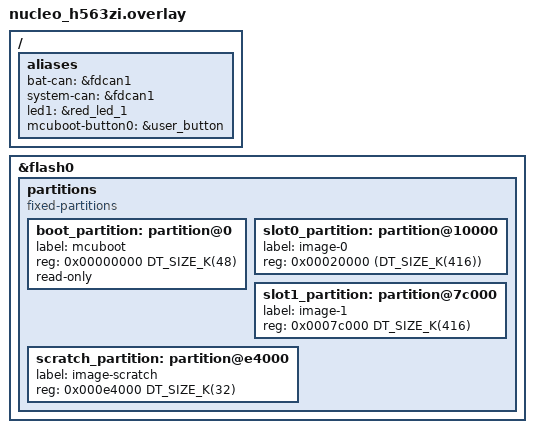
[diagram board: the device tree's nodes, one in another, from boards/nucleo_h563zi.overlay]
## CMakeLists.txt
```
#-------------------------------------------------------------------------------
# Zephyr Example Application
#
# Copyright (c) 2021 Nordic Semiconductor ASA
# SPDX-License-Identifier: Apache-2.0

cmake_minimum_required(VERSION 3.13.1)
find_package(Zephyr REQUIRED HINTS $ENV{ZEPHYR_BASE})

project(app LANGUAGES C)

target_sources(app PRIVATE src/main.c)
target_sources(app PRIVATE src/can.c)
target_sources(app PRIVATE src/sha256.c)
target_sources(app PRIVATE src/utils.c)
```

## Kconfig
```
# Copyright (c) 2021 Nordic Semiconductor ASA
# SPDX-License-Identifier: Apache-2.0
#
# This file is the application Kconfig entry point. All application Kconfig
# options can be defined here or included via other application Kconfig files.
# You can browse these options using the west targets menuconfig (terminal) or
# guiconfig (GUI).

menu "Zephyr"
source "Kconfig.zephyr"

config SAMPLE_CAN_TX_QUEUE_SIZE
	int "Maximum number of CAN frames to enqueue"
	default 3
	range 1 3
	help
	  Maximum number of CAN frames to enqueue for transmission.


endmenu

module = APP
module-str = APP
source "subsys/logging/Kconfig.template.log_config"
```

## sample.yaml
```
# This file is provided so that the application can be compiled using Twister,
# the Zephyr testing tool. In this file, multiple combinations can be specified,
# so that you can easily test all of them locally or in CI.
sample:
  description: CAN bootloader sample application
  name: zcan-boot
common:
  build_only: true
  integration_platforms:
    - stm32h563zi
tests:
  app.default: {}
  app.debug:
    extra_overlay_confs:
      - debug.conf
```

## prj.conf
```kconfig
CONFIG_LOG=y
CONFIG_ASSERT=n
CONFIG_DEBUG=n
CONFIG_DEBUG_THREAD_INFO=n
CONFIG_MAIN_STACK_SIZE=2560
CONFIG_CAN=y
CONFIG_SERIAL=y

CONFIG_FLASH=y
CONFIG_FLASH_MAP=y
CONFIG_FLASH_PAGE_LAYOUT=y
```

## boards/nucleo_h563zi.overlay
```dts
/ {
    aliases {
		bat-can = &fdcan1;
		system-can = &fdcan1;
		led1 = &red_led_1;
		mcuboot-button0 = &user_button;
    };
};

&flash0 {
	partitions {
		compatible = "fixed-partitions";
		#address-cells = <1>;
		#size-cells = <1>;

		boot_partition: partition@0 {
			label = "mcuboot";
			reg = <0x00000000 DT_SIZE_K(48)>;
			read-only;
		};
		/* The MCUBoot swap-move algorithm uses the last 2 sectors
		 * of the primary slot0 for swap status and move.
		 */
		slot0_partition: partition@10000 {
			label = "image-0";
			reg = <0x00020000 (DT_SIZE_K(416))>;
		};
		slot1_partition: partition@7c000 {
			label = "image-1";
			reg = <0x0007c000 DT_SIZE_K(416)>;
		};
		scratch_partition: partition@e4000 {
			label = "image-scratch";
			reg = <0x000e4000 DT_SIZE_K(32)>;
		};
	};
};
```

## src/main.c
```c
/**
 * @file main.c
 * @author Sarthak Et (et-sarthak)
 * @brief Custom bootloader implementation for firmware updates over CAN bus
 * @version 1.0
 * @date 2024-10-05
 * 
 */

#include <string.h>
#include <zephyr/drivers/flash.h>
#include <zephyr/kernel.h>
#include <zephyr/logging/log.h>

#include "../../include/can.h"
#include "../../include/flash_config.h"
#include "../../include/sha256.h"
#include "../../include/utils.h"

LOG_MODULE_REGISTER(main, CONFIG_LOG_MAX_LEVEL);

/*-------------------------MACROS-----------------------------------*/

#define FL_HEADER_LENGTH     0x400U
#define FL_APP_SLOT_ONE_ADDR 0x20000U
#define FL_APP_SLOT_TWO_ADDR 0x7c000U
#define FL_APP_SLOT_SIZE     0x20000U
#define FL_STORAGE_AREA      0x3c000U
#define FL_UNIT_ADDR         16U
#define FL_SECTOR_SIZE       8192U
#define FL_BASE_ADDRESS      0x08000000U
#define FLASH_DEVICE_NODE    DT_CHOSEN(zephyr_flash_controller)

const struct device* flash_dev = DEVICE_DT_GET(FLASH_DEVICE_NODE);
struct tc_sha256_state_struct sha_ctx;
struct tc_sha256_state_struct new_firm;

typedef struct fl_data {
    uint8_t hashA[2][32];
    uint8_t versionA[2][3];
    int size_in_sectors[2];
    bool is_update_req;
}fl_data_t;

typedef enum DfuState {
    DfuStateWaitForHashData = 0,
    DfuStateWaitForFlashData,
    DfuStateWaitForFlashUpdateCmd,
    DfuStateWaitForCheckHashCmd,
    DfuStatesJumpToApp,
    DfuStateWaiting,
} DfuState_e;

fl_data_t fl_data = {
    .hashA = {{0}},
    .versionA = {{0}},
    .size_in_sectors = {0},
};
int cnt = 0;
int slot_index;
int size_in_sectors;
uint8_t hash_value[32] = {0};
uint8_t output_hash[32] = {0};
uint32_t sector_data[FL_SECTOR_SIZE / 4] = {0};
uint32_t app_slot_addr[2] = {FL_APP_SLOT_ONE_ADDR, FL_APP_SLOT_TWO_ADDR};

/*-------------------------------LOCAL API----------------------------------*/

/**
 * @brief           Read data from flash memory
 * @param addr      flash address to read from
 * @param data      pointer to data buffer to store read data
 * @param size      size of data to read in bytes
 * @return          report error in case of failure
 */

 FuncStatus flash_read_data(uint32_t addr, uint32_t* data, uint32_t size) {
    if (addr % FL_UNIT_ADDR != 0) {
        LOG_ERR("Address or size not aligned to FLASH_UNIT_ADDR (%d)\n", FL_UNIT_ADDR);
        return FuncStatusInvalidArgument;
    }
    for (uint32_t i = 0; i < size; i += FL_UNIT_ADDR) {
        int rc = flash_read(flash_dev, addr + i, (uint8_t*)data + i, FL_UNIT_ADDR);
        if (rc != 0) {
            LOG_ERR("Flash read failed (rc=%d)\n", rc);
            return FuncStatusError;
        }
    }
    return FuncStatusOk;
}

/**
 * @brief           Write data to flash memory (sector erase before write)
 * @param addr      flash address to read from
 * @param data      pointer to data buffer to store read data
 * @param size      size of data to read in bytes
 * @return          report error in case of failure
 */
FuncStatus flash_write_sector(uint32_t addr, const uint32_t* data, uint32_t size) {
    if (addr % FL_UNIT_ADDR != 0) {
        LOG_ERR("Address or size not aligned to FLASH_UNIT_ADDR (%d)\n", FL_UNIT_ADDR);
        return FuncStatusInvalidArgument;
    }
    int rc = flash_erase(flash_dev, addr, FL_SECTOR_SIZE);
    if (rc != 0) {
        LOG_ERR("Flash erase failed (rc=%d)\n", rc);
        return FuncStatusError;
    }
    for (uint32_t i = 0; i < size; i += FL_UNIT_ADDR) {
        int rc = flash_write(flash_dev, addr + i, (const uint8_t*)data + i, FL_UNIT_ADDR);
        if (rc != 0) {
            LOG_ERR("Flash write failed at offset %u (rc=%d)\n", i, rc);
            return FuncStatusError;
        }
    }
    return FuncStatusOk;
}


/**
 * @brief            Store incoming hash data
 * @param data       Pointer to incoming data
 * @return           FuncStatus indicating the status of the operation
 */

FuncStatus store_hash(uint8_t* data) {
    if (cnt == 32) {
        slot_index = data[0];
        fl_data.size_in_sectors[slot_index] = data[1];
        memcpy(&fl_data.versionA[slot_index], &data[2], sizeof(fl_data.versionA[0]));
        memcpy(&fl_data.hashA[slot_index][0], &hash_value, sizeof(fl_data.hashA[0]));
        LOG_INF("version %x %x %x", fl_data.versionA[slot_index][0],
                fl_data.versionA[slot_index][1], fl_data.versionA[slot_index][2]);
        LOG_INF("current slot %d", slot_index);
        cnt = 0;
        return FuncStatusCompleted;
    } else {
        memcpy(&hash_value[cnt], data, sizeof(uint64_t));
        cnt = cnt + 8;
        return FuncStatusInProcess;
    }
}
/**
 * @brief             Store incoming flash data into a local buffer
 * @param data        Pointer to incoming data
 * @return            FuncStatus indicating the status of the operation
 */
FuncStatus store_flash(uint8_t* data) {
    if (cnt < (FL_SECTOR_SIZE / 4)) {
        memcpy(&sector_data[cnt], data, sizeof(uint64_t));
        cnt = cnt + 2;
        if (cnt == (FL_SECTOR_SIZE / 4)) {
            return FuncStatusCompleted;
        }
        return FuncStatusInProcess;
    } else if (cnt >= (FL_SECTOR_SIZE / 4)) {
        LOG_ERR("local buffer is full");
        return FuncStatusOutOfMemory;
    }
    return FuncStatusError;
}

/**
 * @brief               Update flash memory with data from the local buffer
 * @param slot_index    Index of the application slot to update
 * @return              FuncStatus indicating the status of the operation
 */

FuncStatus update_flash(uint8_t slot_index) {
    cnt = 0;
    static uint32_t sector_number = 0;

    LOG_INF("writing to flash_sector %d", sector_number);
    tc_sha256_update(&new_firm, (uint8_t*)sector_data, sizeof(sector_data));
    if (flash_write_sector(app_slot_addr[slot_index] + (FL_SECTOR_SIZE * sector_number),
                           sector_data, FL_SECTOR_SIZE) == FuncStatusOk) {
        sector_number++;
        memset(sector_data, 0xFFFFFFFF, sizeof(sector_data));
        if (fl_data.size_in_sectors[slot_index] == sector_number) {
            // All sectors written
            return FuncStatusCompleted;
        }
        return FuncStatusInProcess;
    }
    return FuncStatusError;
}

/**
 * @brief               Check if the computed hash matches the expected hash
 * @return              FuncStatus indicating whether the hashes match
 */
FuncStatus check_hash() {
    tc_sha256_final(output_hash, &new_firm);
    for (int i = 0; i < sizeof(output_hash); i++) {
        k_msleep(10);
        LOG_INF("%02x\t%02x ", output_hash[i], hash_value[i]);
    }
    if (memcmp(output_hash, hash_value, sizeof(output_hash)) == 0) return FuncStatusOk;
    return FuncStatusError;
}

/**
 * @brief               Jump to the application code in the specified slot
 * @param slot_index    Index of the application slot to jump to
 */
void jump_to_app(uint8_t slot_index) {
    LOG_INF("app_slot %x", app_slot_addr[slot_index]);
    void (*app_reset_handler)();
    uint32_t msp =
        *(volatile uint32_t*)(FL_BASE_ADDRESS + app_slot_addr[slot_index] + FL_HEADER_LENGTH);
    uint32_t reset_handler =
        *(volatile uint32_t*)(FL_BASE_ADDRESS + app_slot_addr[slot_index] + FL_HEADER_LENGTH + 4) |
        0x1;

    LOG_INF("msp: %x\n", msp);
    LOG_INF("reset_handler: %x\n", reset_handler);

    // Set the Vector Table Offset Register to the application's vector table
    SCB->VTOR = FL_BASE_ADDRESS + app_slot_addr[slot_index] + FL_HEADER_LENGTH;

    app_reset_handler = (void (*)())reset_handler;
    __disable_irq();
    HAL_DeInit();
    __set_MSP(msp);
    __DSB();
    __ISB();

    app_reset_handler();
}

/**
 * @brief               Find the latest valid firmware version
 * @param version       Pointer to the fl_data structure containing version information
 * @return              Index of the latest valid version (0 or 1), or -1 if both are invalid
 */
static inline int find_latest_version(struct fl_data* version) {
    int versionA_val =
        (version->versionA[0][0] << 16) | (version->versionA[0][1] << 8) | version->versionA[0][2];
    int versionB_val =
        (version->versionA[1][0] << 16) | (version->versionA[1][1] << 8) | version->versionA[1][2];
    int isA_valid = (versionA_val != 0xFFFFFF);
    int isB_valid = (versionB_val != 0xFFFFFF);

    if (isA_valid && !isB_valid) return 0;      // Only A is valid
    if (!isA_valid && isB_valid) return 1;      // Only B is valid
    if (!isA_valid && !isB_valid) return (-1);  // Both invalid: default to A`
    return (memcmp(&versionA_val, &versionB_val, sizeof(int)) > 0) ? 0 : 1;
}

/*-----------------------------DFU STATE_MACHINE--------------------------------*/

/**
 * @brief               Poll for incoming data and manage the DFU state machine
 * @return              FuncStatus indicating the status of the operation
 */
FuncStatus poll_data() {
    FuncStatus fs = FuncStatusNotReady;
    static DfuState_e state = DfuStateWaitForHashData;
    struct frame_packed packed_frame = {0};
    fs = k_msgq_get(&can_receive_q, &packed_frame, K_FOREVER);
    if (fs != FuncStatusOk) {
        LOG_ERR("k_msgq_get failed with error: %d", fs);
        return fs;
    }

    switch (state) {
    case DfuStateWaiting:
        state = packed_frame.state;
        break;

    case DfuStateWaitForHashData:
        if (packed_frame.state != PacketTypeHashData) {
            LOG_WRN("%s: %d: Invalid packet type: %d", __FUNCTION__, __LINE__, packed_frame.state);
            return FuncStatusInvalidState;
        }
        fs = store_hash(packed_frame.data);
        if (fs == FuncStatusCompleted) {
            state = DfuStateWaitForFlashData;
        }
        break;

    case DfuStateWaitForFlashData:
        if (packed_frame.state != PacketTypeFlashData) {
            LOG_WRN("%s: %d: Invalid packet type: %d", __FUNCTION__, __LINE__, packed_frame.state);
            return FuncStatusInvalidState;
        }
        fs = store_flash(packed_frame.data);
        if (fs == FuncStatusCompleted) {
            state = DfuStateWaitForFlashUpdateCmd;
        } else if (fs == FuncStatusInProcess) {
            return fs;
        } else {
            LOG_ERR("Error storing flash data: %d", fs);
            return fs;
        }
        break;

    case DfuStateWaitForFlashUpdateCmd:
        fs = update_flash(slot_index);
        if (fs == FuncStatusCompleted) {
            LOG_INF("All Flash sectors update successful for slot %d", slot_index);
            state = DfuStateWaitForCheckHashCmd;
        } else if (fs == FuncStatusInProcess) {
            state = DfuStateWaitForFlashData;
        } else {
            LOG_ERR("Error updating flash: %d", fs);
            return fs;
        }
        break;

    case DfuStateWaitForCheckHashCmd:
        if (packed_frame.state != PacketTypeCheckHashCmd) {
            LOG_WRN("%s: %d: Invalid packet type: %d", __FUNCTION__, __LINE__, packed_frame.state);
            return FuncStatusInvalidState;
        }
        fs = check_hash();
        if (fs == FuncStatusOk) {
            fl_data.is_update_req = false;
            fs = flash_write_sector(FL_STORAGE_AREA, (uint32_t*)&fl_data, sizeof(fl_data));
            k_msleep(1000);
            if (fs == FuncStatusOk)
                jump_to_app(slot_index);
            else
                LOG_ERR("%s: %d: Failed to write flash data to storage area: %d", __FUNCTION__,
                        __LINE__, fs);
        } else {
            LOG_ERR("Hash check failed.");
        }
        break;

    default:
        LOG_WRN("Unknown CAN ID: %x", packed_frame.state);
        return FuncStatusError;  // Unknown CAN ID
    }
    return FuncStatusOk;
}

/*-----------------------------MAIN THREAD--------------------------------*/

/**
 * @brief Main function to initialize the bootloader and manage firmware updates
 */
int main() {
    int version_idx = 0;
    static uint32_t fl_read_arr[FL_SECTOR_SIZE / 4] = {0};
    if (!tc_sha256_init(&sha_ctx)) {
        LOG_ERR("hash init failed");
    }
    if (!device_is_ready(flash_dev)) {
        printk("Flash device not ready!\n");
        return -ENODEV;
    }
    if (!tc_sha256_init(&new_firm)) {
        LOG_ERR("hash init failed");
    }
    can_init();
    LOG_INF("Welcome to the custom bootloader!");
    k_msleep(10);
    flash_read_data(FL_STORAGE_AREA, (uint32_t*)&fl_data, sizeof(fl_data));

    version_idx = find_latest_version(&fl_data);
    LOG_INF("version_idx: %d", version_idx);
    LOG_INF("update req value %d:", fl_data.is_update_req);
    if (version_idx == (-1) || fl_data.is_update_req == true) {
        LOG_INF("DFU ENTRY");
        k_msleep(10);
        goto polling_start;
    }
    size_in_sectors = fl_data.size_in_sectors[version_idx];
    for (uint8_t i = 0; i < size_in_sectors; i++) {
        flash_read_data((app_slot_addr[version_idx]) + (i * FL_SECTOR_SIZE), fl_read_arr,
                        FL_SECTOR_SIZE);
        tc_sha256_update(&sha_ctx, fl_read_arr, sizeof(fl_read_arr));
    }
    tc_sha256_final(output_hash, &sha_ctx);

    int check = (version_idx == 0) ? memcmp(fl_data.hashA[0], output_hash, sizeof(output_hash))
                                   : memcmp(fl_data.hashA[1], output_hash, sizeof(output_hash));

    if (check == 0) {
        LOG_INF("Hash matches, jumping to app slot %d", version_idx);
        flash_write_sector(FL_STORAGE_AREA, (uint32_t*)&fl_data, sizeof(fl_data));
        k_msleep(1000);
        jump_to_app(version_idx);
    } else {
        LOG_WRN("Hash mismatch, continuing bootloader operations");
    }

polling_start:
    LOG_INF("Starting polling loop...");
    FuncStatus fs = FuncStatusOk;
    while (1) {
        if (fs >= FuncStatusOk) poll_data();
        k_msleep(5);
    }
    LOG_WRN("Unexpected Exit$$$");
    return 0;
}
```

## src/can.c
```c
/**
 * @file can.c
 * @author Sarthak Et (et-sarthak)
 * @brief CAN interface implementation for system communication
 * @version 1.0
 * @date 2024-10-05
 * 
 */

#include "../../include/can.h"
#include "../../include/flash_config.h"

#include <zephyr/device.h>
#include <zephyr/drivers/can.h>
#include <zephyr/kernel.h>
#include <zephyr/logging/log.h>
#include <zephyr/sys/byteorder.h>
#include <zephyr/sys/printk.h>

#define SYSTEM_CANBUS_NODE  DT_ALIAS(system_can)
#define BATTERY_CANBUS_NODE DT_ALIAS(bat_can)
#define CAN_BITRATE_500    500000

K_MSGQ_DEFINE(can_receive_q, sizeof(struct frame_packed), 20, 4);

LOG_MODULE_REGISTER(can, CONFIG_LOG_MAX_LEVEL);

int err;
int sys_filter_id;
int batt_filter_id;

const struct device* system_can_dev = DEVICE_DT_GET(SYSTEM_CANBUS_NODE);
const struct device* batt_can_dev = DEVICE_DT_GET(BATTERY_CANBUS_NODE);

const struct can_filter rx_filter = {.flags = 0U, .id = 0x220, .mask = 0x000};

/**
 * @brief            Callback function to handle received CAN frames for system messages
 * @param dev        Pointer to the CAN device
 * @param frame      Pointer to the received CAN frame
 * @param user_data  User data pointer (not used)
 */
void can_sys_callback(const struct device* dev, struct can_frame* frame, void* user_data) {
    struct frame_packed packed_frame = {0};
    packed_frame.state = ((frame->id - 0x100) / 4);
    memcpy(&packed_frame.data, frame->data, sizeof(frame->data));
    k_msgq_put(&can_receive_q, &packed_frame, K_NO_WAIT);
}

void can_batt_callback(const struct device* dev, struct can_frame* frame, void* user_data) {
    LOG_INF("Received battery CAN frame with ID: 0x%03X", frame->id);
}

/**
 * @brief            Initialize the CAN interfaces for system and battery communication
 * @return           FuncStatus indicating the status of the initialization
 */
FuncStatus can_init() {
    sys_filter_id = can_add_rx_filter(system_can_dev, can_sys_callback, NULL, &rx_filter);
    batt_filter_id = can_add_rx_filter(batt_can_dev, can_batt_callback, NULL, &rx_filter);
    if (!device_is_ready(system_can_dev)) {
        LOG_WRN("CAN device not ready");
    }
    if (!device_is_ready(batt_can_dev)) {
        LOG_WRN("CAN device not ready");
    }
    err = can_set_bitrate(system_can_dev, CAN_BITRATE_500);
    if (err != 0) {
        LOG_WRN("%s %d Error in setting system CAN bitrate %d", __FUNCTION__, __LINE__, err);
    }
    err = can_set_bitrate(batt_can_dev, CAN_BITRATE_500);
    if (err != 0) {
        LOG_WRN("%s %d Error in setting system CAN bitrate %d", __FUNCTION__, __LINE__, err);
    }
    err = can_start(batt_can_dev);
    if (err != 0) {
        LOG_WRN("Error starting CAN controller (err %d)", err);
    }
    err = can_start(system_can_dev);
    if (err != 0) {
        LOG_WRN("Error starting CAN controller (err %d)", err);
        return FuncStatusError;
    }
    return FuncStatusOk;
}


// Not in use currently
/*
int can_write(uint32_t id, uint8_t* data) {
    struct can_frame frame = {0};
    frame.id = id;
    frame.dlc = 8;  // Data length code, max 8 bytes
    memcpy(frame.data, data, frame.dlc);
    return can_send(system_can_dev, &frame, K_FOREVER, NULL, NULL);
}

int send_ack() {
    struct can_frame frame = {0};
    frame.id = 0x020;          // Acknowledgment frame ID
    frame.dlc = 8;             // Data length code, max 8 bytes
    uint32_t ack_data = 0x01;  // Example data
    uint32_t crc = crc32_uint32(ack_data);
    memcpy(frame.data, &ack_data, sizeof(ack_data));
    memcpy(frame.data + sizeof(ack_data), &crc, sizeof(crc));
    return can_send(system_can_dev, &frame, K_FOREVER, NULL, NULL);
}

int send_nack() {
    struct can_frame frame = {0};
    frame.id = 0x020;           // acknowledgment frame ID
    frame.dlc = 8;              // Data length code, max 8 bytes
    uint32_t nack_data = 0x00;  // Example data
    uint32_t crc = crc32_uint32(nack_data);
    memcpy(frame.data, &nack_data, sizeof(nack_data));
    memcpy(frame.data + sizeof(nack_data), &crc, sizeof(crc));

    return can_send(system_can_dev, &frame, K_FOREVER, NULL, NULL);
}
*/
```

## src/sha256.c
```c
/* sha256.c - TinyCrypt SHA-256 crypto hash algorithm implementation */

/*
 *  Copyright (C) 2017 by Intel Corporation, All Rights Reserved.
 *
 *  Redistribution and use in source and binary forms, with or without
 *  modification, are permitted provided that the following conditions are met:
 *
 *    - Redistributions of source code must retain the above copyright notice,
 *     this list of conditions and the following disclaimer.
 *
 *    - Redistributions in binary form must reproduce the above copyright
 *    notice, this list of conditions and the following disclaimer in the
 *    documentation and/or other materials provided with the distribution.
 *
 *    - Neither the name of Intel Corporation nor the names of its contributors
 *    may be used to endorse or promote products derived from this software
 *    without specific prior written permission.
 *
 *  THIS SOFTWARE IS PROVIDED BY THE COPYRIGHT HOLDERS AND CONTRIBUTORS "AS IS"
 *  AND ANY EXPRESS OR IMPLIED WARRANTIES, INCLUDING, BUT NOT LIMITED TO, THE
 *  IMPLIED WARRANTIES OF MERCHANTABILITY AND FITNESS FOR A PARTICULAR PURPOSE
 *  ARE DISCLAIMED. IN NO EVENT SHALL THE COPYRIGHT OWNER OR CONTRIBUTORS BE
 *  LIABLE FOR ANY DIRECT, INDIRECT, INCIDENTAL, SPECIAL, EXEMPLARY, OR
 *  CONSEQUENTIAL DAMAGES (INCLUDING, BUT NOT LIMITED TO, PROCUREMENT OF
 *  SUBSTITUTE GOODS OR SERVICES; LOSS OF USE, DATA, OR PROFITS; OR BUSINESS
 *  INTERRUPTION) HOWEVER CAUSED AND ON ANY THEORY OF LIABILITY, WHETHER IN
 *  CONTRACT, STRICT LIABILITY, OR TORT (INCLUDING NEGLIGENCE OR OTHERWISE)
 *  ARISING IN ANY WAY OUT OF THE USE OF THIS SOFTWARE, EVEN IF ADVISED OF THE
 *  POSSIBILITY OF SUCH DAMAGE.
 */


 #include "../../include/sha256.h"
 #include "../../include/utils.h"
#include "constants.h"
// #include <zephyr/kernel.h>

static void compress(unsigned int *iv, const uint8_t *data);

int tc_sha256_init(TCSha256State_t s)
{
	/* input sanity check: */
	if (s == (TCSha256State_t) 0) {
		return TC_CRYPTO_FAIL;
	}

	/*
	 * Setting the initial state values.
	 * These values correspond to the first 32 bits of the fractional parts
	 * of the square roots of the first 8 primes: 2, 3, 5, 7, 11, 13, 17
	 * and 19.
	 */
	_set((uint8_t *) s, 0x00, sizeof(*s));
	s->iv[0] = 0x6a09e667;
	s->iv[1] = 0xbb67ae85;
	s->iv[2] = 0x3c6ef372;
	s->iv[3] = 0xa54ff53a;
	s->iv[4] = 0x510e527f;
	s->iv[5] = 0x9b05688c;
	s->iv[6] = 0x1f83d9ab;
	s->iv[7] = 0x5be0cd19;

	return TC_CRYPTO_SUCCESS;
}

int tc_sha256_update(TCSha256State_t s, const uint8_t *data, size_t datalen)
{
	/* input sanity check: */
	if (s == (TCSha256State_t) 0 ||
	    data == (void *) 0) {
		return TC_CRYPTO_FAIL;
	} else if (datalen == 0) {
		return TC_CRYPTO_SUCCESS;
	}

	while (datalen-- > 0) {
		s->leftover[s->leftover_offset++] = *(data++);
		// printf("data = %02x\n", s->leftover[s->leftover_offset - 1]);
		// k_msleep(2);
		if (s->leftover_offset >= TC_SHA256_BLOCK_SIZE) {
			compress(s->iv, s->leftover);
			s->leftover_offset = 0;
			s->bits_hashed += (TC_SHA256_BLOCK_SIZE << 3);
		}
	}

	return TC_CRYPTO_SUCCESS;
}

int tc_sha256_final(uint8_t *digest, TCSha256State_t s)
{
	unsigned int i;

	/* input sanity check: */
	if (digest == (uint8_t *) 0 ||
	    s == (TCSha256State_t) 0) {
		return TC_CRYPTO_FAIL;
	}

	s->bits_hashed += (s->leftover_offset << 3);

	s->leftover[s->leftover_offset++] = 0x80; /* always room for one byte */
	if (s->leftover_offset > (sizeof(s->leftover) - 8)) {
		/* there is not room for all the padding in this block */
		_set(s->leftover + s->leftover_offset, 0x00,
		     sizeof(s->leftover) - s->leftover_offset);
		compress(s->iv, s->leftover);
		s->leftover_offset = 0;
	}

	/* add the padding and the length in big-Endian format */
	_set(s->leftover + s->leftover_offset, 0x00,
	     sizeof(s->leftover) - 8 - s->leftover_offset);
	s->leftover[sizeof(s->leftover) - 1] = (uint8_t)(s->bits_hashed);
	s->leftover[sizeof(s->leftover) - 2] = (uint8_t)(s->bits_hashed >> 8);
	s->leftover[sizeof(s->leftover) - 3] = (uint8_t)(s->bits_hashed >> 16);
	s->leftover[sizeof(s->leftover) - 4] = (uint8_t)(s->bits_hashed >> 24);
	s->leftover[sizeof(s->leftover) - 5] = (uint8_t)(s->bits_hashed >> 32);
	s->leftover[sizeof(s->leftover) - 6] = (uint8_t)(s->bits_hashed >> 40);
	s->leftover[sizeof(s->leftover) - 7] = (uint8_t)(s->bits_hashed >> 48);
	s->leftover[sizeof(s->leftover) - 8] = (uint8_t)(s->bits_hashed >> 56);

	/* hash the padding and length */
	compress(s->iv, s->leftover);

	/* copy the iv out to digest */
	for (i = 0; i < TC_SHA256_STATE_BLOCKS; ++i) {
		unsigned int t = *((unsigned int *) &s->iv[i]);
		*digest++ = (uint8_t)(t >> 24);
		*digest++ = (uint8_t)(t >> 16);
		*digest++ = (uint8_t)(t >> 8);
		*digest++ = (uint8_t)(t);
	}

	/* destroy the current state */
	_set(s, 0, sizeof(*s));

	return TC_CRYPTO_SUCCESS;
}

/*
 * Initializing SHA-256 Hash constant words K.
 * These values correspond to the first 32 bits of the fractional parts of the
 * cube roots of the first 64 primes between 2 and 311.
 */
static const unsigned int k256[64] = {
	0x428a2f98, 0x71374491, 0xb5c0fbcf, 0xe9b5dba5, 0x3956c25b, 0x59f111f1,
	0x923f82a4, 0xab1c5ed5, 0xd807aa98, 0x12835b01, 0x243185be, 0x550c7dc3,
	0x72be5d74, 0x80deb1fe, 0x9bdc06a7, 0xc19bf174, 0xe49b69c1, 0xefbe4786,
	0x0fc19dc6, 0x240ca1cc, 0x2de92c6f, 0x4a7484aa, 0x5cb0a9dc, 0x76f988da,
	0x983e5152, 0xa831c66d, 0xb00327c8, 0xbf597fc7, 0xc6e00bf3, 0xd5a79147,
	0x06ca6351, 0x14292967, 0x27b70a85, 0x2e1b2138, 0x4d2c6dfc, 0x53380d13,
	0x650a7354, 0x766a0abb, 0x81c2c92e, 0x92722c85, 0xa2bfe8a1, 0xa81a664b,
	0xc24b8b70, 0xc76c51a3, 0xd192e819, 0xd6990624, 0xf40e3585, 0x106aa070,
	0x19a4c116, 0x1e376c08, 0x2748774c, 0x34b0bcb5, 0x391c0cb3, 0x4ed8aa4a,
	0x5b9cca4f, 0x682e6ff3, 0x748f82ee, 0x78a5636f, 0x84c87814, 0x8cc70208,
	0x90befffa, 0xa4506ceb, 0xbef9a3f7, 0xc67178f2
};

static inline unsigned int ROTR(unsigned int a, unsigned int n)
{
	return (((a) >> n) | ((a) << (32 - n)));
}

#define Sigma0(a)(ROTR((a), 2) ^ ROTR((a), 13) ^ ROTR((a), 22))
#define Sigma1(a)(ROTR((a), 6) ^ ROTR((a), 11) ^ ROTR((a), 25))
#define sigma0(a)(ROTR((a), 7) ^ ROTR((a), 18) ^ ((a) >> 3))
#define sigma1(a)(ROTR((a), 17) ^ ROTR((a), 19) ^ ((a) >> 10))

#define Ch(a, b, c)(((a) & (b)) ^ ((~(a)) & (c)))
#define Maj(a, b, c)(((a) & (b)) ^ ((a) & (c)) ^ ((b) & (c)))

static inline unsigned int BigEndian(const uint8_t **c)
{
	unsigned int n = 0;

	n = (((unsigned int)(*((*c)++))) << 24);
	n |= ((unsigned int)(*((*c)++)) << 16);
	n |= ((unsigned int)(*((*c)++)) << 8);
	n |= ((unsigned int)(*((*c)++)));
	return n;
}

static void compress(unsigned int *iv, const uint8_t *data)
{
	unsigned int a, b, c, d, e, f, g, h;
	unsigned int s0, s1;
	unsigned int t1, t2;
	unsigned int work_space[16];
	unsigned int n;
	unsigned int i;

	a = iv[0]; b = iv[1]; c = iv[2]; d = iv[3];
	e = iv[4]; f = iv[5]; g = iv[6]; h = iv[7];

	for (i = 0; i < 16; ++i) {
		n = BigEndian(&data);
		t1 = work_space[i] = n;
		t1 += h + Sigma1(e) + Ch(e, f, g) + k256[i];
		t2 = Sigma0(a) + Maj(a, b, c);
		h = g; g = f; f = e; e = d + t1;
		d = c; c = b; b = a; a = t1 + t2;
	}

	for ( ; i < 64; ++i) {
		s0 = work_space[(i+1)&0x0f];
		s0 = sigma0(s0);
		s1 = work_space[(i+14)&0x0f];
		s1 = sigma1(s1);

		t1 = work_space[i&0xf] += s0 + s1 + work_space[(i+9)&0xf];
		t1 += h + Sigma1(e) + Ch(e, f, g) + k256[i];
		t2 = Sigma0(a) + Maj(a, b, c);
		h = g; g = f; f = e; e = d + t1;
		d = c; c = b; b = a; a = t1 + t2;
	}

	iv[0] += a; iv[1] += b; iv[2] += c; iv[3] += d;
	iv[4] += e; iv[5] += f; iv[6] += g; iv[7] += h;
}
```

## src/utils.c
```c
/* utils.c - TinyCrypt platform-dependent run-time operations */

/*
 *  Copyright (C) 2017 by Intel Corporation, All Rights Reserved.
 *
 *  Redistribution and use in source and binary forms, with or without
 *  modification, are permitted provided that the following conditions are met:
 *
 *    - Redistributions of source code must retain the above copyright notice,
 *     this list of conditions and the following disclaimer.
 *
 *    - Redistributions in binary form must reproduce the above copyright
 *    notice, this list of conditions and the following disclaimer in the
 *    documentation and/or other materials provided with the distribution.
 *
 *    - Neither the name of Intel Corporation nor the names of its contributors
 *    may be used to endorse or promote products derived from this software
 *    without specific prior written permission.
 *
 *  THIS SOFTWARE IS PROVIDED BY THE COPYRIGHT HOLDERS AND CONTRIBUTORS "AS IS"
 *  AND ANY EXPRESS OR IMPLIED WARRANTIES, INCLUDING, BUT NOT LIMITED TO, THE
 *  IMPLIED WARRANTIES OF MERCHANTABILITY AND FITNESS FOR A PARTICULAR PURPOSE
 *  ARE DISCLAIMED. IN NO EVENT SHALL THE COPYRIGHT OWNER OR CONTRIBUTORS BE
 *  LIABLE FOR ANY DIRECT, INDIRECT, INCIDENTAL, SPECIAL, EXEMPLARY, OR
 *  CONSEQUENTIAL DAMAGES (INCLUDING, BUT NOT LIMITED TO, PROCUREMENT OF
 *  SUBSTITUTE GOODS OR SERVICES; LOSS OF USE, DATA, OR PROFITS; OR BUSINESS
 *  INTERRUPTION) HOWEVER CAUSED AND ON ANY THEORY OF LIABILITY, WHETHER IN
 *  CONTRACT, STRICT LIABILITY, OR TORT (INCLUDING NEGLIGENCE OR OTHERWISE)
 *  ARISING IN ANY WAY OUT OF THE USE OF THIS SOFTWARE, EVEN IF ADVISED OF THE
 *  POSSIBILITY OF SUCH DAMAGE.
 */

#include "../../include/utils.h"
#include "constants.h"

#include <string.h>

#define MASK_TWENTY_SEVEN 0x1b

unsigned int _copy(uint8_t *to, unsigned int to_len,
		   const uint8_t *from, unsigned int from_len)
{
	if (from_len <= to_len) {
		(void)memcpy(to, from, from_len);
		return from_len;
	} else {
		return TC_CRYPTO_FAIL;
	}
}

void _set(void *to, uint8_t val, unsigned int len)
{
	(void)memset(to, val, len);
}	

/*
 * Doubles the value of a byte for values up to 127.
 */
uint8_t _double_byte(uint8_t a)
{
	return ((a<<1) ^ ((a>>7) * MASK_TWENTY_SEVEN));
}

int _compare(const uint8_t *a, const uint8_t *b, size_t size)
{
	const uint8_t *tempa = a;
	const uint8_t *tempb = b;
	uint8_t result = 0;

	for (unsigned int i = 0; i < size; i++) {
		result |= tempa[i] ^ tempb[i];
	}
	return result;
}
```
